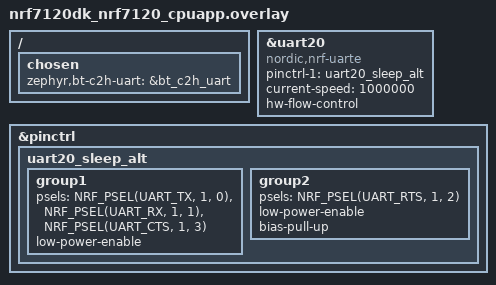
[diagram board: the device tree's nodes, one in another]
/*
 * Copyright (c) 2026 Nordic Semiconductor ASA
 *
 * SPDX-License-Identifier: LicenseRef-Nordic-5-Clause
 */

bt_c2h_uart: &uart20 {
	compatible = "nordic,nrf-uarte";
	pinctrl-1 = <&uart20_sleep_alt>;
	current-speed = <1000000>;
	status = "okay";
	hw-flow-control;
};

/ {
	chosen {
		zephyr,bt-c2h-uart = &bt_c2h_uart;
		/delete-property/ zephyr,console;
		/delete-property/ zephyr,shell-uart;
		/delete-property/ zephyr,uart-mcumgr;
		/delete-property/ zephyr,bt-mon-uart;
	};
};

/* NCSDK-36190: keep RTS pulled up while the UART sleeps between packets. */
&pinctrl {
	uart20_sleep_alt: uart20_sleep_alt {
		group1 {
			psels = <NRF_PSEL(UART_TX, 1, 0)>,
				<NRF_PSEL(UART_RX, 1, 1)>,
				<NRF_PSEL(UART_CTS, 1, 3)>;
			low-power-enable;
		};
		group2 {
			psels = <NRF_PSEL(UART_RTS, 1, 2)>;
			low-power-enable;
			bias-pull-up;
		};
	};
};
